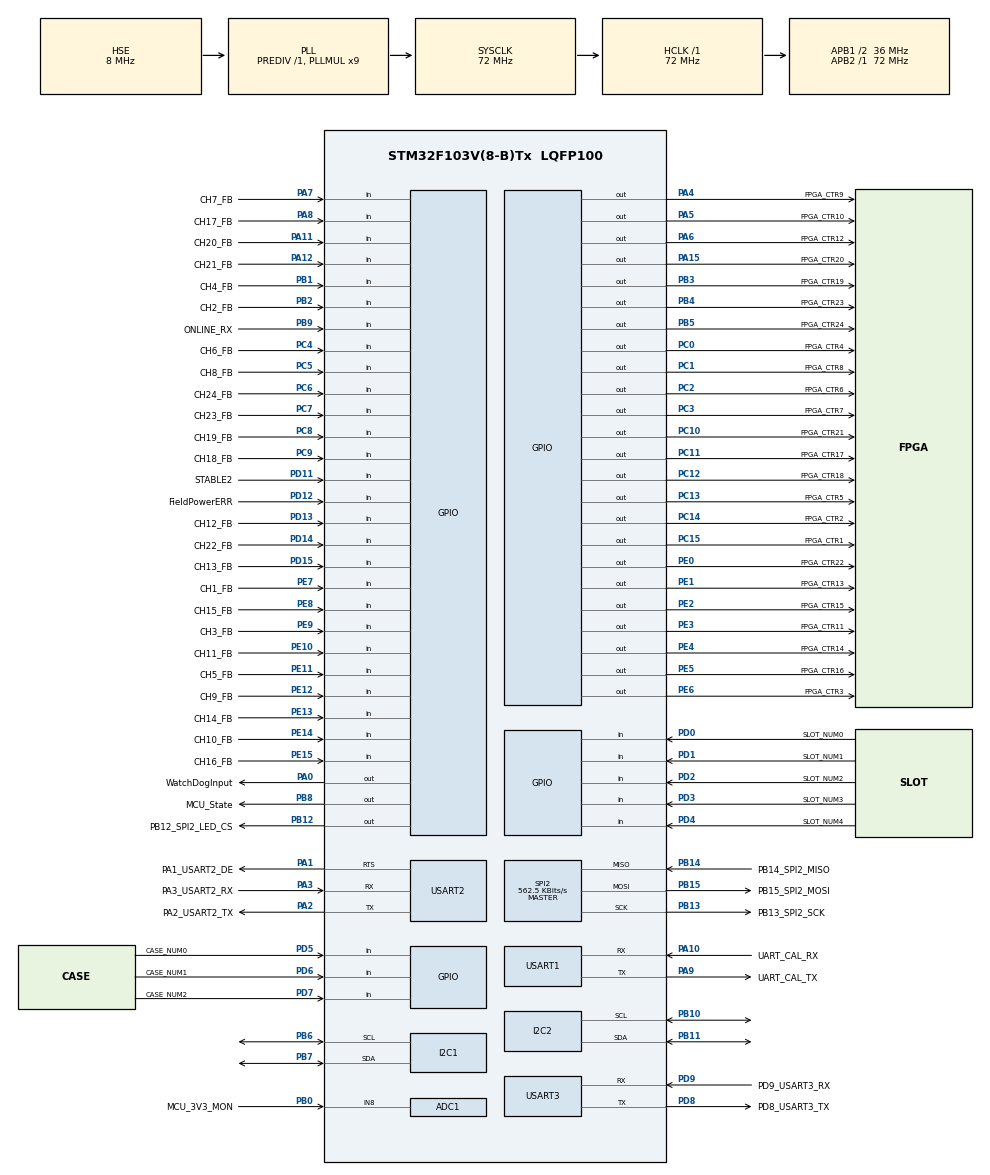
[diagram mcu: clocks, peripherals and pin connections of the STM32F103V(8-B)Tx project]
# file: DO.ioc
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ADC1.Channel-0\#ChannelRegularConversion=ADC_CHANNEL_8
ADC1.NbrOfConversionFlag=1
ADC1.Rank-0\#ChannelRegularConversion=1
ADC1.SamplingTime-0\#ChannelRegularConversion=ADC_SAMPLETIME_1CYCLE_5
ADC1.master=1
Dma.Request0=SPI2_TX
Dma.Request1=SPI2_RX
Dma.SPI2_RX.1.Direction=DMA_PERIPH_TO_MEMORY
Dma.SPI2_RX.1.Instance=DMA1_Channel4
Dma.SPI2_RX.1.MemDataAlignment=DMA_MDATAALIGN_BYTE
Dma.SPI2_RX.1.MemInc=DMA_MINC_ENABLE
Dma.SPI2_RX.1.Mode=DMA_NORMAL
Dma.SPI2_RX.1.PeriphDataAlignment=DMA_PDATAALIGN_BYTE
Dma.SPI2_RX.1.PeriphInc=DMA_PINC_DISABLE
Dma.SPI2_RX.1.Priority=DMA_PRIORITY_LOW
Dma.SPI2_TX.0.Direction=DMA_MEMORY_TO_PERIPH
Dma.SPI2_TX.0.Instance=DMA1_Channel5
Dma.SPI2_TX.0.MemDataAlignment=DMA_MDATAALIGN_BYTE
Dma.SPI2_TX.0.MemInc=DMA_MINC_ENABLE
Dma.SPI2_TX.0.Mode=DMA_NORMAL
Dma.SPI2_TX.0.PeriphDataAlignment=DMA_PDATAALIGN_BYTE
Dma.SPI2_TX.0.PeriphInc=DMA_PINC_DISABLE
Dma.SPI2_TX.0.Priority=DMA_PRIORITY_LOW
Mcu.Family=STM32F1
Mcu.Name=STM32F103V(8-B)Tx
Mcu.Package=LQFP100
NVIC.PriorityGroup=NVIC_PRIORITYGROUP_2
NVIC.TIM1_BRK_IRQn=true\:1\:2\:true\:false\:true\:true\:true
NVIC.TIM1_UP_IRQn=true\:2\:3\:true\:false\:true\:true\:true
NVIC.USART2_IRQn=true\:2\:0\:true\:false\:true\:true\:true
NVIC.USART3_IRQn=true\:3\:3\:true\:false\:true\:true\:true
OSC_IN.GPIO_Label=OSC_IN
OSC_IN.Mode=HSE-External-Oscillator
OSC_IN.Signal=RCC_OSC_IN
OSC_OUT.GPIO_Label=NC
OSC_OUT.Mode=HSE-External-Oscillator
OSC_OUT.Signal=RCC_OSC_OUT
PA0-WKUP.GPIO_Label=WatchDogInput
PA0-WKUP.GPIO_PuPd=GPIO_PULLUP
PA0-WKUP.GPIO_Speed=GPIO_SPEED_FREQ_HIGH
PA0-WKUP.PinState=GPIO_PIN_SET
PA0-WKUP.Signal=GPIO_Output
PA1.GPIO_Label=PA1_USART2_DE
PA1.Mode=RTS_Only
PA1.Signal=USART2_RTS
PA10.GPIO_Label=UART_CAL_RX
PA10.Mode=Asynchronous
PA10.Signal=USART1_RX
PA11.GPIO_Label=CH20_FB
PA11.GPIO_PuPd=GPIO_PULLDOWN
PA11.Signal=GPIO_Input
PA12.GPIO_Label=CH21_FB
PA12.GPIO_PuPd=GPIO_PULLDOWN
PA12.Signal=GPIO_Input
PA13.GPIO_Label=SWDIO
PA13.Mode=Serial_Wire
PA13.Signal=SYS_JTMS-SWDIO
PA14.GPIO_Label=SWCLK
PA14.Mode=Serial_Wire
PA14.Signal=SYS_JTCK-SWCLK
PA15.GPIO_Label=FPGA_CTR20
PA15.GPIO_PuPd=GPIO_PULLUP
PA15.GPIO_Speed=GPIO_SPEED_FREQ_HIGH
PA15.PinState=GPIO_PIN_SET
PA15.Signal=GPIO_Output
PA2.GPIO_Label=PA2_USART2_TX
PA2.Mode=Asynchronous
PA2.Signal=USART2_TX
PA3.GPIO_Label=PA3_USART2_RX
PA3.Mode=Asynchronous
PA3.Signal=USART2_RX
PA4.GPIO_Label=FPGA_CTR9
PA4.GPIO_PuPd=GPIO_PULLUP
PA4.GPIO_Speed=GPIO_SPEED_FREQ_HIGH
PA4.PinState=GPIO_PIN_SET
PA4.Signal=GPIO_Output
PA5.GPIO_Label=FPGA_CTR10
PA5.GPIO_PuPd=GPIO_PULLUP
PA5.GPIO_Speed=GPIO_SPEED_FREQ_HIGH
PA5.PinState=GPIO_PIN_SET
PA5.Signal=GPIO_Output
PA6.GPIO_Label=FPGA_CTR12
PA6.GPIO_PuPd=GPIO_PULLUP
PA6.GPIO_Speed=GPIO_SPEED_FREQ_HIGH
PA6.PinState=GPIO_PIN_SET
PA6.Signal=GPIO_Output
PA7.GPIO_Label=CH7_FB
PA7.GPIO_PuPd=GPIO_PULLDOWN
PA7.Signal=GPIO_Input
PA8.GPIO_Label=CH17_FB
PA8.GPIO_PuPd=GPIO_PULLDOWN
PA8.Signal=GPIO_Input
PA9.GPIO_Label=UART_CAL_TX
PA9.Mode=Asynchronous
PA9.Signal=USART1_TX
PB0.GPIO_Label=MCU_3V3_MON
PB0.Signal=ADCx_IN8
PB1.GPIO_Label=CH4_FB
PB1.GPIO_PuPd=GPIO_PULLDOWN
PB1.Signal=GPIO_Input
PB10.Mode=I2C
PB10.Signal=I2C2_SCL
PB11.Mode=I2C
PB11.Signal=I2C2_SDA
PB12.GPIO_Label=PB12_SPI2_LED_CS
PB12.Signal=GPIO_Output
PB13.GPIO_Label=PB13_SPI2_SCK
PB13.Mode=Full_Duplex_Master
PB13.Signal=SPI2_SCK
PB14.GPIO_Label=PB14_SPI2_MISO
PB14.Mode=Full_Duplex_Master
PB14.Signal=SPI2_MISO
PB15.GPIO_Label=PB15_SPI2_MOSI
PB15.Mode=Full_Duplex_Master
PB15.Signal=SPI2_MOSI
PB2.GPIO_Label=CH2_FB
PB2.GPIO_PuPd=GPIO_PULLDOWN
PB2.Signal=GPIO_Input
PB3.GPIO_Label=FPGA_CTR19
PB3.GPIO_PuPd=GPIO_PULLUP
PB3.GPIO_Speed=GPIO_SPEED_FREQ_HIGH
PB3.PinState=GPIO_PIN_SET
PB3.Signal=GPIO_Output
PB4.GPIO_Label=FPGA_CTR23
PB4.GPIO_PuPd=GPIO_PULLUP
PB4.GPIO_Speed=GPIO_SPEED_FREQ_HIGH
PB4.PinState=GPIO_PIN_SET
PB4.Signal=GPIO_Output
PB5.GPIO_Label=FPGA_CTR24
PB5.GPIO_PuPd=GPIO_PULLUP
PB5.GPIO_Speed=GPIO_SPEED_FREQ_HIGH
PB5.PinState=GPIO_PIN_SET
PB5.Signal=GPIO_Output
PB6.Mode=I2C
PB6.Signal=I2C1_SCL
PB7.Mode=I2C
PB7.Signal=I2C1_SDA
PB8.GPIO_Label=MCU_State
PB8.Signal=GPIO_Output
PB9.GPIO_Label=ONLINE_RX
PB9.Signal=GPIO_Input
PC0.GPIO_Label=FPGA_CTR4
PC0.GPIO_PuPd=GPIO_PULLUP
PC0.GPIO_Speed=GPIO_SPEED_FREQ_HIGH
PC0.PinState=GPIO_PIN_SET
PC0.Signal=GPIO_Output
PC1.GPIO_Label=FPGA_CTR8
PC1.GPIO_PuPd=GPIO_PULLUP
PC1.GPIO_Speed=GPIO_SPEED_FREQ_HIGH
PC1.PinState=GPIO_PIN_SET
PC1.Signal=GPIO_Output
PC10.GPIO_Label=FPGA_CTR21
PC10.GPIO_PuPd=GPIO_PULLUP
PC10.GPIO_Speed=GPIO_SPEED_FREQ_HIGH
PC10.PinState=GPIO_PIN_SET
PC10.Signal=GPIO_Output
PC11.GPIO_Label=FPGA_CTR17
PC11.GPIO_PuPd=GPIO_PULLUP
PC11.GPIO_Speed=GPIO_SPEED_FREQ_HIGH
PC11.PinState=GPIO_PIN_SET
PC11.Signal=GPIO_Output
PC12.GPIO_Label=FPGA_CTR18
PC12.GPIO_PuPd=GPIO_PULLUP
PC12.GPIO_Speed=GPIO_SPEED_FREQ_HIGH
PC12.PinState=GPIO_PIN_SET
PC12.Signal=GPIO_Output
PC13-TAMPER-RTC.GPIO_Label=FPGA_CTR5
PC13-TAMPER-RTC.GPIO_PuPd=GPIO_PULLUP
PC13-TAMPER-RTC.GPIO_Speed=GPIO_SPEED_FREQ_HIGH
PC13-TAMPER-RTC.PinState=GPIO_PIN_SET
PC13-TAMPER-RTC.Signal=GPIO_Output
PC14-OSC32_IN.GPIO_Label=FPGA_CTR2
PC14-OSC32_IN.GPIO_PuPd=GPIO_PULLUP
PC14-OSC32_IN.GPIO_Speed=GPIO_SPEED_FREQ_HIGH
PC14-OSC32_IN.PinState=GPIO_PIN_SET
PC14-OSC32_IN.Signal=GPIO_Output
PC15-OSC32_OUT.GPIO_Label=FPGA_CTR1
PC15-OSC32_OUT.GPIO_PuPd=GPIO_PULLUP
PC15-OSC32_OUT.GPIO_Speed=GPIO_SPEED_FREQ_HIGH
PC15-OSC32_OUT.PinState=GPIO_PIN_SET
PC15-OSC32_OUT.Signal=GPIO_Output
PC2.GPIO_Label=FPGA_CTR6
PC2.GPIO_PuPd=GPIO_PULLUP
PC2.GPIO_Speed=GPIO_SPEED_FREQ_HIGH
PC2.PinState=GPIO_PIN_SET
PC2.Signal=GPIO_Output
PC3.GPIO_Label=FPGA_CTR7
PC3.GPIO_PuPd=GPIO_PULLUP
PC3.GPIO_Speed=GPIO_SPEED_FREQ_HIGH
PC3.PinState=GPIO_PIN_SET
PC3.Signal=GPIO_Output
PC4.GPIO_Label=CH6_FB
PC4.GPIO_PuPd=GPIO_PULLDOWN
PC4.Signal=GPIO_Input
PC5.GPIO_Label=CH8_FB
PC5.GPIO_PuPd=GPIO_PULLDOWN
PC5.Signal=GPIO_Input
PC6.GPIO_Label=CH24_FB
PC6.GPIO_PuPd=GPIO_PULLDOWN
PC6.Signal=GPIO_Input
PC7.GPIO_Label=CH23_FB
PC7.GPIO_PuPd=GPIO_PULLDOWN
PC7.Signal=GPIO_Input
PC8.GPIO_Label=CH19_FB
PC8.GPIO_PuPd=GPIO_PULLDOWN
PC8.Signal=GPIO_Input
PC9.GPIO_Label=CH18_FB
PC9.GPIO_PuPd=GPIO_PULLDOWN
PC9.Signal=GPIO_Input
PD0.GPIO_Label=SLOT_NUM0
PD0.GPIO_PuPd=GPIO_PULLDOWN
PD0.Signal=GPIO_Input
PD1.GPIO_Label=SLOT_NUM1
PD1.GPIO_PuPd=GPIO_PULLDOWN
PD1.Signal=GPIO_Input
PD10.GPIO_Label=PA12_USART3_DE
PD10.Signal=USART3_CK
PD11.GPIO_Label=STABLE2
PD11.Signal=GPIO_Input
PD12.GPIO_Label=FieldPowerERR
PD12.GPIO_PuPd=GPIO_PULLDOWN
PD12.Signal=GPIO_Input
PD13.GPIO_Label=CH12_FB
PD13.GPIO_PuPd=GPIO_PULLDOWN
PD13.Signal=GPIO_Input
PD14.GPIO_Label=CH22_FB
PD14.GPIO_PuPd=GPIO_PULLDOWN
PD14.Signal=GPIO_Input
PD15.GPIO_Label=CH13_FB
PD15.GPIO_PuPd=GPIO_PULLDOWN
PD15.Signal=GPIO_Input
PD2.GPIO_Label=SLOT_NUM2
PD2.GPIO_PuPd=GPIO_PULLDOWN
PD2.Signal=GPIO_Input
PD3.GPIO_Label=SLOT_NUM3
PD3.GPIO_PuPd=GPIO_PULLDOWN
PD3.Signal=GPIO_Input
PD4.GPIO_Label=SLOT_NUM4
PD4.GPIO_PuPd=GPIO_PULLDOWN
PD4.Signal=GPIO_Input
PD5.GPIO_Label=CASE_NUM0
PD5.GPIO_PuPd=GPIO_PULLDOWN
PD5.Signal=GPIO_Input
PD6.GPIO_Label=CASE_NUM1
PD6.GPIO_PuPd=GPIO_PULLDOWN
PD6.Signal=GPIO_Input
PD7.GPIO_Label=CASE_NUM2
PD7.GPIO_PuPd=GPIO_PULLDOWN
PD7.Signal=GPIO_Input
PD8.GPIO_Label=PD8_USART3_TX
PD8.Mode=Asynchronous
PD8.Signal=USART3_TX
PD9.GPIO_Label=PD9_USART3_RX
PD9.Mode=Asynchronous
PD9.Signal=USART3_RX
PE0.GPIO_Label=FPGA_CTR22
PE0.GPIO_PuPd=GPIO_PULLUP
PE0.GPIO_Speed=GPIO_SPEED_FREQ_HIGH
PE0.PinState=GPIO_PIN_SET
PE0.Signal=GPIO_Output
PE1.GPIO_Label=FPGA_CTR13
PE1.GPIO_PuPd=GPIO_PULLUP
PE1.GPIO_Speed=GPIO_SPEED_FREQ_HIGH
PE1.PinState=GPIO_PIN_SET
PE1.Signal=GPIO_Output
PE10.GPIO_Label=CH11_FB
PE10.GPIO_PuPd=GPIO_PULLDOWN
PE10.Signal=GPIO_Input
PE11.GPIO_Label=CH5_FB
PE11.GPIO_PuPd=GPIO_PULLDOWN
PE11.Signal=GPIO_Input
PE12.GPIO_Label=CH9_FB
PE12.GPIO_PuPd=GPIO_PULLDOWN
PE12.Signal=GPIO_Input
PE13.GPIO_Label=CH14_FB
PE13.GPIO_PuPd=GPIO_PULLDOWN
PE13.Signal=GPIO_Input
PE14.GPIO_Label=CH10_FB
PE14.GPIO_PuPd=GPIO_PULLDOWN
PE14.Signal=GPIO_Input
PE15.GPIO_Label=CH16_FB
PE15.GPIO_PuPd=GPIO_PULLDOWN
PE15.Signal=GPIO_Input
PE2.GPIO_Label=FPGA_CTR15
PE2.GPIO_PuPd=GPIO_PULLUP
PE2.GPIO_Speed=GPIO_SPEED_FREQ_HIGH
PE2.PinState=GPIO_PIN_SET
PE2.Signal=GPIO_Output
PE3.GPIO_Label=FPGA_CTR11
PE3.GPIO_PuPd=GPIO_PULLUP
PE3.GPIO_Speed=GPIO_SPEED_FREQ_HIGH
PE3.PinState=GPIO_PIN_SET
PE3.Signal=GPIO_Output
PE4.GPIO_Label=FPGA_CTR14
PE4.GPIO_PuPd=GPIO_PULLUP
PE4.GPIO_Speed=GPIO_SPEED_FREQ_HIGH
PE4.PinState=GPIO_PIN_SET
PE4.Signal=GPIO_Output
PE5.GPIO_Label=FPGA_CTR16
PE5.GPIO_PuPd=GPIO_PULLUP
PE5.GPIO_Speed=GPIO_SPEED_FREQ_HIGH
PE5.PinState=GPIO_PIN_SET
PE5.Signal=GPIO_Output
PE6.GPIO_Label=FPGA_CTR3
PE6.GPIO_PuPd=GPIO_PULLUP
PE6.GPIO_Speed=GPIO_SPEED_FREQ_HIGH
PE6.PinState=GPIO_PIN_SET
PE6.Signal=GPIO_Output
PE7.GPIO_Label=CH1_FB
PE7.GPIO_PuPd=GPIO_PULLDOWN
PE7.Signal=GPIO_Input
PE8.GPIO_Label=CH15_FB
PE8.GPIO_PuPd=GPIO_PULLDOWN
PE8.Signal=GPIO_Input
PE9.GPIO_Label=CH3_FB
PE9.GPIO_PuPd=GPIO_PULLDOWN
PE9.Signal=GPIO_Input
ProjectManager.HeapSize=0x200
ProjectManager.StackSize=0x400
ProjectManager.TargetToolchain=MDK-ARM V5
RCC.ADCPresc=RCC_ADCPCLK2_DIV6
RCC.AHBFreq_Value=72000000
RCC.APB1CLKDivider=RCC_HCLK_DIV2
RCC.APB1Freq_Value=36000000
RCC.APB1TimFreq_Value=72000000
RCC.APB2Freq_Value=72000000
RCC.APB2TimFreq_Value=72000000
RCC.HCLKFreq_Value=72000000
RCC.PLLMUL=RCC_PLL_MUL9
RCC.PLLSourceVirtual=RCC_PLLSOURCE_HSE
RCC.SYSCLKFreq_VALUE=72000000
RCC.SYSCLKSource=RCC_SYSCLKSOURCE_PLLCLK
RCC.USBFreq_Value=72000000
RealThread.RT-Thread.3.1.3.RTAaThreadCcRTOSJjkernel=true
RealThread.RT-Thread.3.1.3.RTAaThreadCcRTOSJjshell=true
SH.ADCx_IN8.0=ADC1_IN8,IN8
SPI2.BaudRatePrescaler=SPI_BAUDRATEPRESCALER_64
SPI2.CalculateBaudRate=562.5 KBits/s
SPI2.Direction=SPI_DIRECTION_2LINES
SPI2.Mode=SPI_MODE_MASTER
SPI2.VirtualType=VM_MASTER
TIM1.Period=50000
TIM1.Prescaler=72
USART1.VirtualMode=VM_ASYNC
USART2.VirtualMode=VM_ASYNC
USART3.VirtualMode=VM_ASYNC
VP_RealThread.RT-Thread_VS_RTOSJjRTAaThread_3.1.3.Mode=RTOSJjRTAaThread
VP_TIM1_VS_ClockSourceINT.Mode=Internal
board=custom

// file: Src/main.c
/* USER CODE BEGIN Header */
/**
  ******************************************************************************
  * @file           : main.c
  * @brief          : Main program body
  ******************************************************************************
  * @attention
  *
  * <h2><center>&copy; Copyright (c) 2020 STMicroelectronics.
  * All rights reserved.</center></h2>
  *
  * This software component is licensed by ST under BSD 3-Clause license,
  * the "License"; You may not use this file except in compliance with the
  * License. You may obtain a copy of the License at:
  *                        opensource.org/licenses/BSD-3-Clause
  *
  ******************************************************************************
  */
/* USER CODE END Header */

#include "main.h"
#include "adc.h"
#include "dma.h"
#include "i2c.h"
#include "spi.h"
#include "tim.h"
#include "usart.h"
#include "gpio.h"

void SystemClock_Config(void);

int main(void)
{

  /* MCU Configuration--------------------------------------------------------*/

  /* Reset of all peripherals, Initializes the Flash interface and the Systick. */
  HAL_Init();

  /* Configure the system clock */
  SystemClock_Config();

  /* Initialize all configured peripherals */
  MX_GPIO_Init();
  MX_DMA_Init();
  MX_ADC1_Init();
  MX_I2C1_Init();
  MX_SPI2_Init();
  MX_USART1_UART_Init();
  MX_USART2_UART_Init();
  MX_USART3_UART_Init();
  MX_I2C2_Init();
  MX_TIM1_Init();

  /* Infinite loop */
  /* USER CODE BEGIN WHILE */
	HAL_TIM_Base_Start_IT(&htim1);

  while (1)
  {
    /* USER CODE END WHILE */

    /* USER CODE BEGIN 3 */
		/*GPIOA*/

		//HAL_Delay(50); /* 延时500ms*/
		//HAL_GPIO_WritePin(GPIOA, WatchDogInput_Pin, GPIO_PIN_SET);
		HAL_Delay(5);
  }
  /* USER CODE END 3 */
}

void SystemClock_Config(void)
{
  RCC_OscInitTypeDef RCC_OscInitStruct = {0};
  RCC_ClkInitTypeDef RCC_ClkInitStruct = {0};
  RCC_PeriphCLKInitTypeDef PeriphClkInit = {0};

  /** Initializes the CPU, AHB and APB busses clocks
  */
  RCC_OscInitStruct.OscillatorType = RCC_OSCILLATORTYPE_HSE;
  RCC_OscInitStruct.HSEState = RCC_HSE_ON;
  RCC_OscInitStruct.HSEPredivValue = RCC_HSE_PREDIV_DIV1;
  RCC_OscInitStruct.HSIState = RCC_HSI_ON;
  RCC_OscInitStruct.PLL.PLLState = RCC_PLL_ON;
  RCC_OscInitStruct.PLL.PLLSource = RCC_PLLSOURCE_HSE;
  RCC_OscInitStruct.PLL.PLLMUL = RCC_PLL_MUL9;
  if (HAL_RCC_OscConfig(&RCC_OscInitStruct) != HAL_OK)
  {
    Error_Handler();
  }
  /** Initializes the CPU, AHB and APB busses clocks
  */
  RCC_ClkInitStruct.ClockType = RCC_CLOCKTYPE_HCLK|RCC_CLOCKTYPE_SYSCLK
                              |RCC_CLOCKTYPE_PCLK1|RCC_CLOCKTYPE_PCLK2;
  RCC_ClkInitStruct.SYSCLKSource = RCC_SYSCLKSOURCE_PLLCLK;
  RCC_ClkInitStruct.AHBCLKDivider = RCC_SYSCLK_DIV1;
  RCC_ClkInitStruct.APB1CLKDivider = RCC_HCLK_DIV2;
  RCC_ClkInitStruct.APB2CLKDivider = RCC_HCLK_DIV1;

  if (HAL_RCC_ClockConfig(&RCC_ClkInitStruct, FLASH_LATENCY_2) != HAL_OK)
  {
    Error_Handler();
  }
  PeriphClkInit.PeriphClockSelection = RCC_PERIPHCLK_ADC;
  PeriphClkInit.AdcClockSelection = RCC_ADCPCLK2_DIV6;
  if (HAL_RCCEx_PeriphCLKConfig(&PeriphClkInit) != HAL_OK)
  {
    Error_Handler();
  }
}

void Error_Handler(void)
{
}

/************************ (C) COPYRIGHT STMicroelectronics *****END OF FILE****/
